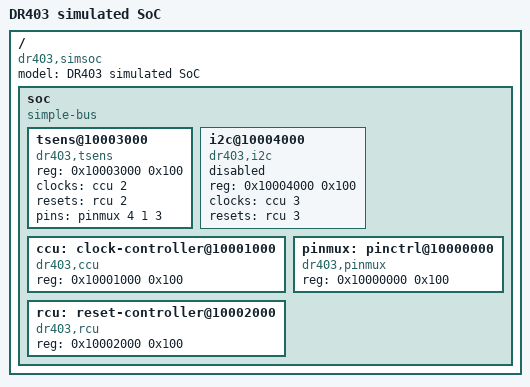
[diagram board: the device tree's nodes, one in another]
// soc.dts - F4-35: the devicetree of the course's simulated SoC (socsim.cc). All compatible
// strings are this course's own ("dr403,..."), and so are the clock and reset numbers: on a real
// SoC they come from the vendor's binding header and the TRM's clock chapter.
// The temperature sensor is listed BEFORE the providers it needs, on purpose (deferred probe).
/ {
    model = "DR403 simulated SoC";
    compatible = "dr403,simsoc";
    #address-cells = <1>;
    #size-cells = <1>;

    soc {
        compatible = "simple-bus";
        #address-cells = <1>;
        #size-cells = <1>;
        ranges;

        tsens@10003000 {
            compatible = "dr403,tsens";
            reg = <0x10003000 0x100>;
            clocks = <&ccu 2>;
            resets = <&rcu 2>;
            pins = <&pinmux 4 1 3>;
        };
        i2c@10004000 {
            compatible = "dr403,i2c";
            reg = <0x10004000 0x100>;
            clocks = <&ccu 3>;
            resets = <&rcu 3>;
            status = "disabled";
        };
        ccu: clock-controller@10001000 {
            compatible = "dr403,ccu";
            reg = <0x10001000 0x100>;
            #clock-cells = <1>;
        };
        rcu: reset-controller@10002000 {
            compatible = "dr403,rcu";
            reg = <0x10002000 0x100>;
            #reset-cells = <1>;
        };
        pinmux: pinctrl@10000000 {
            compatible = "dr403,pinmux";
            reg = <0x10000000 0x100>;
        };
    };
};
